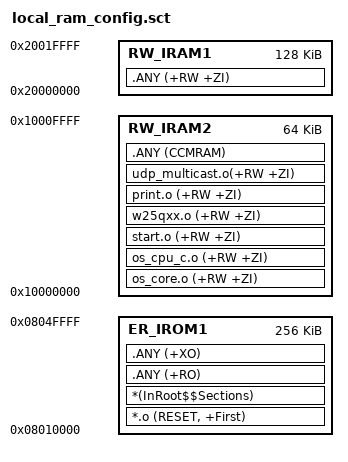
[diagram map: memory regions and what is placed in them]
; *************************************************************
; *** Scatter-Loading Description File generated by uVision ***
; *************************************************************

LR_IROM1 0x08010000 0x00040000  {    ; load region size_region
	ER_IROM1 0x08010000 0x00040000  {  ; load address = execution address
	*.o (RESET, +First)
	*(InRoot$$Sections)
	.ANY (+RO)
	.ANY (+XO)
	}
	RW_IRAM1 0x20000000 0x00020000  {  ; RW data
	.ANY (+RW +ZI)
	}
	RW_IRAM2 0x10000000 0x00010000  {
	os_core.o    (+RW +ZI)	
	os_cpu_c.o   (+RW +ZI)
	start.o      (+RW +ZI)	
	w25qxx.o     (+RW +ZI)
	print.o      (+RW +ZI)
	udp_multicast.o(+RW +ZI)
	
	.ANY (CCMRAM)
	}
}

